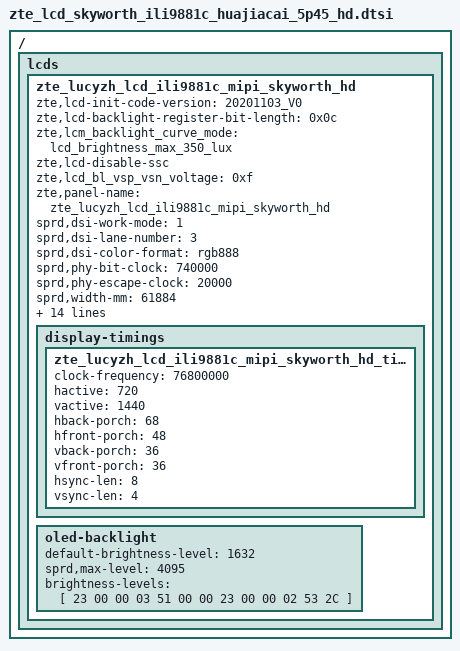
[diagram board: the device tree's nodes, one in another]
/ { lcds {
	zte_lucyzh_lcd_ili9881c_mipi_skyworth_hd: zte_lucyzh_lcd_ili9881c_mipi_skyworth_hd {
		zte,lcd-init-code-version = "20201103_V0";
		zte,lcd-backlight-register-bit-length = <0x0c>;
		zte,lcm_backlight_curve_mode = "lcd_brightness_max_350_lux";
		zte,lcd-disable-ssc;
		zte,lcd_bl_vsp_vsn_voltage = <0xf>;
		zte,panel-name = "zte_lucyzh_lcd_ili9881c_mipi_skyworth_hd";

		sprd,dsi-work-mode = <1>; /* video burst mode*/
		sprd,dsi-lane-number = <3>;
		sprd,dsi-color-format = "rgb888";

		sprd,phy-bit-clock = <740000>;	/* kbps */
		sprd,phy-escape-clock = <20000>;/* kHz */

		sprd,width-mm = <61884>;
		sprd,height-mm = <123768>;

		sprd,esd-check-enable = <1>;/* 0:close , 1:open */
		sprd,esd-check-mode = <1>;/* 0:REG ,1:TE  */
		sprd,esd-check-period = <1000>;
		sprd,esd-check-register = <0x0A>;
		sprd,esd-check-value = <0x9C>;
		sprd,reset-on-sequence = <1 5>, <0 5>, <1 20>;
		sprd,reset-off-sequence = <0 0>, <0 0>, <1 20>;
		sprd,initial-command = [
39 00 00 04 ff 98 81 03
39 00 00 02 01 00
39 00 00 02 02 00
39 00 00 02 03 56
39 00 00 02 04 53
39 00 00 02 05 53
39 00 00 02 06 06
39 00 00 02 07 00
39 00 00 02 08 00
39 00 00 02 09 00
39 00 00 02 0a 00
39 00 00 02 0b 00
39 00 00 02 0c 00
39 00 00 02 0d 00
39 00 00 02 0e 00
39 00 00 02 0f 08
39 00 00 02 10 08
39 00 00 02 11 00
39 00 00 02 12 00
39 00 00 02 13 00
39 00 00 02 14 00
39 00 00 02 15 08
39 00 00 02 16 08
39 00 00 02 17 00
39 00 00 02 18 08
39 00 00 02 19 00
39 00 00 02 1a 00
39 00 00 02 1b 00
39 00 00 02 1c 00
39 00 00 02 1d 00
39 00 00 02 1e c0
39 00 00 02 1f c0
39 00 00 02 20 02
39 00 00 02 21 05
39 00 00 02 22 02
39 00 00 02 23 05
39 00 00 02 24 86
39 00 00 02 25 86
39 00 00 02 26 86
39 00 00 02 27 86
39 00 00 02 28 3b
39 00 00 02 29 03
39 00 00 02 2a 00
39 00 00 02 2b 00
39 00 00 02 2c 00
39 00 00 02 2d 00
39 00 00 02 2e 00
39 00 00 02 2f 00
39 00 00 02 30 00
39 00 00 02 31 00
39 00 00 02 32 00
39 00 00 02 33 00
39 00 00 02 34 03
39 00 00 02 35 00
39 00 00 02 36 00
39 00 00 02 37 00
39 00 00 02 38 3c
39 00 00 02 39 00
39 00 00 02 3a 00
39 00 00 02 3b 00
39 00 00 02 3c 00
39 00 00 02 3d 00
39 00 00 02 3e 00
39 00 00 02 3f 00
39 00 00 02 40 00
39 00 00 02 41 00
39 00 00 02 42 00
39 00 00 02 43 00
39 00 00 02 44 00
39 00 00 02 50 01
39 00 00 02 51 23
39 00 00 02 52 45
39 00 00 02 53 67
39 00 00 02 54 89
39 00 00 02 55 ab
39 00 00 02 56 01
39 00 00 02 57 23
39 00 00 02 58 45
39 00 00 02 59 67
39 00 00 02 5a 89
39 00 00 02 5b ab
39 00 00 02 5c cd
39 00 00 02 5d ef
39 00 00 02 5e 01
39 00 00 02 5f 01
39 00 00 02 60 08
39 00 00 02 61 00
39 00 00 02 62 02
39 00 00 02 63 0f
39 00 00 02 64 0e
39 00 00 02 65 0d
39 00 00 02 66 0c
39 00 00 02 67 06
39 00 00 02 68 02
39 00 00 02 69 02
39 00 00 02 6a 02
39 00 00 02 6b 02
39 00 00 02 6c 02
39 00 00 02 6d 02
39 00 00 02 6e 02
39 00 00 02 6f 02
39 00 00 02 70 02
39 00 00 02 71 02
39 00 00 02 72 00
39 00 00 02 73 02
39 00 00 02 74 02
39 00 00 02 75 01
39 00 00 02 76 06
39 00 00 02 77 00
39 00 00 02 78 02
39 00 00 02 79 0c
39 00 00 02 7a 0d
39 00 00 02 7b 0e
39 00 00 02 7c 0f
39 00 00 02 7d 0a
39 00 00 02 7e 02
39 00 00 02 7f 02
39 00 00 02 80 02
39 00 00 02 81 02
39 00 00 02 82 02
39 00 00 02 83 02
39 00 00 02 84 02
39 00 00 02 85 02
39 00 00 02 86 02
39 00 00 02 87 02
39 00 00 02 88 00
39 00 00 02 89 02
39 00 00 02 8a 02
39 00 00 04 ff 98 81 04
39 00 00 02 00 00
39 00 00 02 6c 15
39 00 00 02 6e 2b
39 00 00 02 6f 25
39 00 00 02 3a a4
39 00 00 02 8d 1f
39 00 00 02 87 ba
39 00 00 02 26 76
39 00 00 02 b2 d1
39 00 00 02 88 0b
39 00 00 02 33 14
39 00 00 02 35 17
39 00 00 02 38 01
39 00 00 02 39 00
39 00 00 02 7a 0f
39 00 00 02 b5 02
39 00 00 02 31 25
39 00 00 02 3b 98
39 00 00 04 ff 98 81 01
39 00 00 02 22 0a
39 00 00 02 2e f0
39 00 00 02 31 00
39 00 00 02 53 4f
39 00 00 02 55 4f
39 00 00 02 50 bf
39 00 00 02 51 ba
39 00 00 02 60 10
39 00 00 02 61 00
39 00 00 02 62 20
39 00 00 02 63 00
39 00 00 02 a0 00
39 00 00 02 a1 20
39 00 00 02 a2 32
39 00 00 02 a3 16
39 00 00 02 a4 1c
39 00 00 02 a5 31
39 00 00 02 a6 25
39 00 00 02 a7 25
39 00 00 02 a8 9e
39 00 00 02 a9 1b
39 00 00 02 aa 27
39 00 00 02 ab 7d
39 00 00 02 ac 1b
39 00 00 02 ad 1a
39 00 00 02 ae 4f
39 00 00 02 af 24
39 00 00 02 b0 29
39 00 00 02 b1 50
39 00 00 02 b2 5f
39 00 00 02 b3 3f
39 00 00 02 c0 00
39 00 00 02 c1 20
39 00 00 02 c2 32
39 00 00 02 c3 16
39 00 00 02 c4 1c
39 00 00 02 c5 31
39 00 00 02 c6 25
39 00 00 02 c7 25
39 00 00 02 c8 9e
39 00 00 02 c9 1b
39 00 00 02 ca 27
39 00 00 02 cb 7d
39 00 00 02 cc 1b
39 00 00 02 cd 1a
39 00 00 02 ce 4f
39 00 00 02 cf 24
39 00 00 02 d0 29
39 00 00 02 d1 50
39 00 00 02 d2 5f
39 00 00 02 d3 3f
39 00 00 04 FF 98 81 02
39 00 00 02 06 20
39 00 00 02 07 00
39 00 00 04 ff 98 81 00
39 00 00 03 68 02 01
39 00 00 02 35 00
39 00 00 03 51 00 00
39 00 00 02 53 24
39 00 00 02 55 00
39 00 00 03 5e 00 04
23 78 00 02 11 00
23 20 00 02 29 00
			];
		sprd,sleep-in-command = [
			13 0A 00 01 28
			13 78 00 01 10
			39 00 00 04 FF 98 81 01
			23 01 00 02 58 01
			39 00 00 04 FF 98 81 00
			];
		sprd,sleep-out-command = [
			13 78 00 01 11
			13 64 00 01 29
			];

		display-timings {
			zte_lucyzh_lcd_ili9881c_mipi_skyworth_hd_timing0: timing0 {
			clock-frequency = <76800000>;
			hactive = <720>;
			vactive = <1440>;
			hback-porch = <68>;
			hfront-porch = <48>;
			vback-porch = <36>;
			vfront-porch = <36>;
			hsync-len = <8>;
			vsync-len = <4>;
			};
		};
		oled-backlight {
			default-brightness-level = <1632>;
			sprd,max-level = <4095>;
			brightness-levels = [
				23 00 00 03 51 00 00
				23 00 00 02 53 2C
			];
		};
	};
};};

